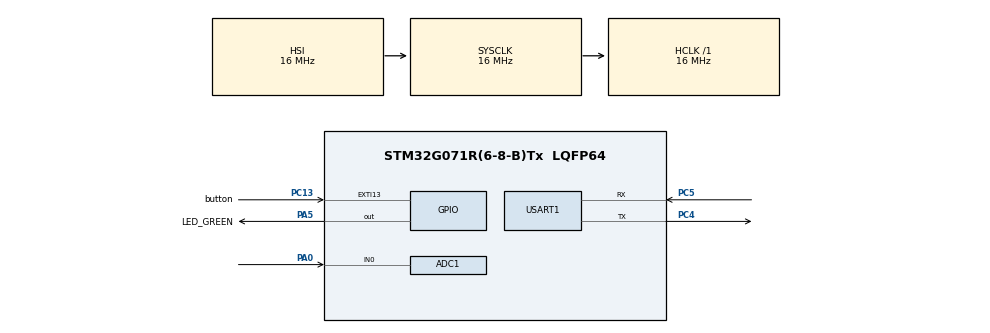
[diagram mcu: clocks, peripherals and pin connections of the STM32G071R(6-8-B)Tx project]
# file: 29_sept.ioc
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ADC1.Channel-0\#ChannelRegularConversion=ADC_CHANNEL_0
ADC1.ClockPrescaler=ADC_CLOCK_SYNC_PCLK_DIV2
ADC1.ContinuousConvMode=DISABLE
ADC1.NbrOfConversionFlag=1
ADC1.Rank-0\#ChannelRegularConversion=1
ADC1.SamplingTime-0\#ChannelRegularConversion=ADC_SAMPLINGTIME_COMMON_1
ADC1.SamplingTimeCommon1=ADC_SAMPLETIME_1CYCLE_5
ADC1.SelectedChannel=ADC_CHANNEL_0
ADC1.master=1
Mcu.Family=STM32G0
Mcu.Name=STM32G071R(6-8-B)Tx
Mcu.Package=LQFP64
NVIC.EXTI4_15_IRQn=true\:3\:0\:true\:false\:true\:true\:true
PA0.Mode=IN0
PA0.Signal=ADC1_IN0
PA13.GPIO_Label=TMS
PA13.Signal=SYS_SWDIO
PA14-BOOT0.GPIO_Label=TCK
PA14-BOOT0.Signal=SYS_SWCLK
PA2.GPIO_Label=USART2_TX [STLK_TX]
PA2.Signal=USART2_TX
PA3.GPIO_Label=USART2_RX [STLK_RX]
PA3.Signal=USART2_RX
PA5.GPIO_Label=LED_GREEN
PA5.GPIO_Speed=GPIO_SPEED_FREQ_HIGH
PA5.Signal=GPIO_Output
PC13.GPIO_Label=button
PC13.Signal=GPXTI13
PC14-OSC32_IN\ (PC14).Signal=RCC_OSC32_IN
PC15-OSC32_OUT\ (PC15).Signal=RCC_OSC32_OUT
PC4.Mode=Asynchronous
PC4.Signal=USART1_TX
PC5.Mode=Asynchronous
PC5.Signal=USART1_RX
PF0-OSC_IN\ (PF0).GPIO_Label=MCO
PF0-OSC_IN\ (PF0).Signal=RCC_OSC_IN
ProjectManager.HeapSize=0x200
ProjectManager.StackSize=0x400
ProjectManager.TargetToolchain=STM32CubeIDE
RCC.AHBFreq_Value=16000000
RCC.CortexFreq_Value=16000000
RCC.EXTERNAL_CLOCK_VALUE=12288000
RCC.HCLKFreq_Value=16000000
RCC.HSE_VALUE=8000000
RCC.HSI_VALUE=16000000
RCC.LSE_VALUE=32768
RCC.SYSCLKFreq_VALUE=16000000
RCC.VCOOutputFreq_Value=128000000
TIM6.Period=65535
TIM6.Prescaler=16000-1
USART1.VirtualMode-Asynchronous=VM_ASYNC
VP_SYS_VS_DBSignals.Mode=DisableDeadBatterySignals
VP_TIM6_VS_ClockSourceINT.Mode=Enable_Timer
board=NUCLEO-G071RB

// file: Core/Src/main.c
/* USER CODE BEGIN Header */
/**
  ******************************************************************************
  * @file           : main.c
  * @brief          : Main program body
  ******************************************************************************
  * @attention
  *
  * <h2><center>&copy; Copyright (c) 2023 STMicroelectronics.
  * All rights reserved.</center></h2>
  *
  * This software component is licensed by ST under BSD 3-Clause license,
  * the "License"; You may not use this file except in compliance with the
  * License. You may obtain a copy of the License at:
  *                        opensource.org/licenses/BSD-3-Clause
  *
  ******************************************************************************
  */
/* USER CODE END Header */
#include "main.h"

ADC_HandleTypeDef hadc1;

TIM_HandleTypeDef htim6;

UART_HandleTypeDef huart1;

void SystemClock_Config(void);
static void MX_GPIO_Init(void);
static void MX_USART1_UART_Init(void);
static void MX_ADC1_Init(void);
static void MX_TIM6_Init(void);

int main(void)
{

  /* MCU Configuration--------------------------------------------------------*/

  /* Reset of all peripherals, Initializes the Flash interface and the Systick. */
  HAL_Init();

  /* Configure the system clock */
  SystemClock_Config();

  /* Initialize all configured peripherals */
  MX_GPIO_Init();
  MX_USART1_UART_Init();
  MX_ADC1_Init();
  MX_TIM6_Init();
  /* USER CODE BEGIN 2 */
  HAL_TIM_Base_Start(&htim6);
  HAL_ADC_Start(&hadc1);
  /* USER CODE END 2 */

  /* Infinite loop */
  while (1)
  {

  }
}

void SystemClock_Config(void)
{
  RCC_OscInitTypeDef RCC_OscInitStruct = {0};
  RCC_ClkInitTypeDef RCC_ClkInitStruct = {0};
  RCC_PeriphCLKInitTypeDef PeriphClkInit = {0};

  /** Configure the main internal regulator output voltage
  */
  HAL_PWREx_ControlVoltageScaling(PWR_REGULATOR_VOLTAGE_SCALE1);
  /** Initializes the RCC Oscillators according to the specified parameters
  * in the RCC_OscInitTypeDef structure.
  */
  RCC_OscInitStruct.OscillatorType = RCC_OSCILLATORTYPE_HSI;
  RCC_OscInitStruct.HSIState = RCC_HSI_ON;
  RCC_OscInitStruct.HSIDiv = RCC_HSI_DIV1;
  RCC_OscInitStruct.HSICalibrationValue = RCC_HSICALIBRATION_DEFAULT;
  RCC_OscInitStruct.PLL.PLLState = RCC_PLL_NONE;
  if (HAL_RCC_OscConfig(&RCC_OscInitStruct) != HAL_OK)
  {
    Error_Handler();
  }
  /** Initializes the CPU, AHB and APB buses clocks
  */
  RCC_ClkInitStruct.ClockType = RCC_CLOCKTYPE_HCLK|RCC_CLOCKTYPE_SYSCLK
                              |RCC_CLOCKTYPE_PCLK1;
  RCC_ClkInitStruct.SYSCLKSource = RCC_SYSCLKSOURCE_HSI;
  RCC_ClkInitStruct.AHBCLKDivider = RCC_SYSCLK_DIV1;
  RCC_ClkInitStruct.APB1CLKDivider = RCC_HCLK_DIV1;

  if (HAL_RCC_ClockConfig(&RCC_ClkInitStruct, FLASH_LATENCY_0) != HAL_OK)
  {
    Error_Handler();
  }
  /** Initializes the peripherals clocks
  */
  PeriphClkInit.PeriphClockSelection = RCC_PERIPHCLK_USART1|RCC_PERIPHCLK_ADC;
  PeriphClkInit.Usart1ClockSelection = RCC_USART1CLKSOURCE_PCLK1;
  PeriphClkInit.AdcClockSelection = RCC_ADCCLKSOURCE_SYSCLK;
  if (HAL_RCCEx_PeriphCLKConfig(&PeriphClkInit) != HAL_OK)
  {
    Error_Handler();
  }
}

static void MX_ADC1_Init(void)
{

  ADC_ChannelConfTypeDef sConfig = {0};

  /** Configure the global features of the ADC (Clock, Resolution, Data Alignment and number of conversion)
  */
  hadc1.Instance = ADC1;
  hadc1.Init.ClockPrescaler = ADC_CLOCK_SYNC_PCLK_DIV2;
  hadc1.Init.Resolution = ADC_RESOLUTION_12B;
  hadc1.Init.DataAlign = ADC_DATAALIGN_RIGHT;
  hadc1.Init.ScanConvMode = ADC_SCAN_DISABLE;
  hadc1.Init.EOCSelection = ADC_EOC_SINGLE_CONV;
  hadc1.Init.LowPowerAutoWait = DISABLE;
  hadc1.Init.LowPowerAutoPowerOff = DISABLE;
  hadc1.Init.ContinuousConvMode = DISABLE;
  hadc1.Init.NbrOfConversion = 1;
  hadc1.Init.DiscontinuousConvMode = DISABLE;
  hadc1.Init.ExternalTrigConv = ADC_SOFTWARE_START;
  hadc1.Init.ExternalTrigConvEdge = ADC_EXTERNALTRIGCONVEDGE_NONE;
  hadc1.Init.DMAContinuousRequests = DISABLE;
  hadc1.Init.Overrun = ADC_OVR_DATA_PRESERVED;
  hadc1.Init.SamplingTimeCommon1 = ADC_SAMPLETIME_1CYCLE_5;
  hadc1.Init.SamplingTimeCommon2 = ADC_SAMPLETIME_1CYCLE_5;
  hadc1.Init.OversamplingMode = DISABLE;
  hadc1.Init.TriggerFrequencyMode = ADC_TRIGGER_FREQ_HIGH;
  if (HAL_ADC_Init(&hadc1) != HAL_OK)
  {
    Error_Handler();
  }
  /** Configure Regular Channel
  */
  sConfig.Channel = ADC_CHANNEL_0;
  sConfig.Rank = ADC_REGULAR_RANK_1;
  sConfig.SamplingTime = ADC_SAMPLINGTIME_COMMON_1;
  if (HAL_ADC_ConfigChannel(&hadc1, &sConfig) != HAL_OK)
  {
    Error_Handler();
  }

}

static void MX_TIM6_Init(void)
{

  TIM_MasterConfigTypeDef sMasterConfig = {0};

  htim6.Instance = TIM6;
  htim6.Init.Prescaler = 16000-1;
  htim6.Init.CounterMode = TIM_COUNTERMODE_UP;
  htim6.Init.Period = 65535;
  htim6.Init.AutoReloadPreload = TIM_AUTORELOAD_PRELOAD_DISABLE;
  if (HAL_TIM_Base_Init(&htim6) != HAL_OK)
  {
    Error_Handler();
  }
  sMasterConfig.MasterOutputTrigger = TIM_TRGO_RESET;
  sMasterConfig.MasterSlaveMode = TIM_MASTERSLAVEMODE_DISABLE;
  if (HAL_TIMEx_MasterConfigSynchronization(&htim6, &sMasterConfig) != HAL_OK)
  {
    Error_Handler();
  }

}

static void MX_USART1_UART_Init(void)
{

  huart1.Instance = USART1;
  huart1.Init.BaudRate = 115200;
  huart1.Init.WordLength = UART_WORDLENGTH_8B;
  huart1.Init.StopBits = UART_STOPBITS_1;
  huart1.Init.Parity = UART_PARITY_NONE;
  huart1.Init.Mode = UART_MODE_TX_RX;
  huart1.Init.HwFlowCtl = UART_HWCONTROL_NONE;
  huart1.Init.OverSampling = UART_OVERSAMPLING_16;
  huart1.Init.OneBitSampling = UART_ONE_BIT_SAMPLE_DISABLE;
  huart1.Init.ClockPrescaler = UART_PRESCALER_DIV1;
  huart1.AdvancedInit.AdvFeatureInit = UART_ADVFEATURE_NO_INIT;
  if (HAL_UART_Init(&huart1) != HAL_OK)
  {
    Error_Handler();
  }
  if (HAL_UARTEx_SetTxFifoThreshold(&huart1, UART_TXFIFO_THRESHOLD_1_8) != HAL_OK)
  {
    Error_Handler();
  }
  if (HAL_UARTEx_SetRxFifoThreshold(&huart1, UART_RXFIFO_THRESHOLD_1_8) != HAL_OK)
  {
    Error_Handler();
  }
  if (HAL_UARTEx_DisableFifoMode(&huart1) != HAL_OK)
  {
    Error_Handler();
  }

}

static void MX_GPIO_Init(void)
{
  GPIO_InitTypeDef GPIO_InitStruct = {0};

  /* GPIO Ports Clock Enable */
  __HAL_RCC_GPIOC_CLK_ENABLE();
  __HAL_RCC_GPIOF_CLK_ENABLE();
  __HAL_RCC_GPIOA_CLK_ENABLE();

  /*Configure GPIO pin Output Level */
  HAL_GPIO_WritePin(LED_GREEN_GPIO_Port, LED_GREEN_Pin, GPIO_PIN_RESET);

  /*Configure GPIO pin : button_Pin */
  GPIO_InitStruct.Pin = button_Pin;
  GPIO_InitStruct.Mode = GPIO_MODE_IT_RISING;
  GPIO_InitStruct.Pull = GPIO_NOPULL;
  HAL_GPIO_Init(button_GPIO_Port, &GPIO_InitStruct);

  /*Configure GPIO pins : USART2_TX_Pin USART2_RX_Pin */
  GPIO_InitStruct.Pin = USART2_TX_Pin|USART2_RX_Pin;
  GPIO_InitStruct.Mode = GPIO_MODE_AF_PP;
  GPIO_InitStruct.Pull = GPIO_NOPULL;
  GPIO_InitStruct.Speed = GPIO_SPEED_FREQ_LOW;
  GPIO_InitStruct.Alternate = GPIO_AF1_USART2;
  HAL_GPIO_Init(GPIOA, &GPIO_InitStruct);

  /*Configure GPIO pin : LED_GREEN_Pin */
  GPIO_InitStruct.Pin = LED_GREEN_Pin;
  GPIO_InitStruct.Mode = GPIO_MODE_OUTPUT_PP;
  GPIO_InitStruct.Pull = GPIO_NOPULL;
  GPIO_InitStruct.Speed = GPIO_SPEED_FREQ_HIGH;
  HAL_GPIO_Init(LED_GREEN_GPIO_Port, &GPIO_InitStruct);

  /* EXTI interrupt init*/
  HAL_NVIC_SetPriority(EXTI4_15_IRQn, 3, 0);
  HAL_NVIC_EnableIRQ(EXTI4_15_IRQn);

}

void Error_Handler(void)
{
  __disable_irq();
  while (1)
  {
  }
}

/************************ (C) COPYRIGHT STMicroelectronics *****END OF FILE****/
